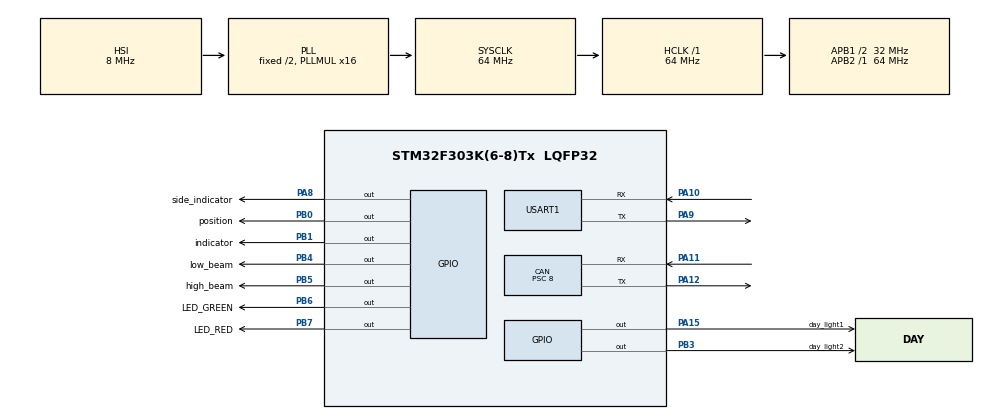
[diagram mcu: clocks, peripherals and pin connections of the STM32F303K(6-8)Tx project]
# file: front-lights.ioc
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CAN.BS1=CAN_BS1_6TQ
CAN.CalculateBaudRate=500000
CAN.CalculateTimeBit=2000
CAN.CalculateTimeQuantum=250.0
CAN.Prescaler=8
CAN.SJW=CAN_SJW_1TQ
Mcu.Family=STM32F3
Mcu.Name=STM32F303K(6-8)Tx
Mcu.Package=LQFP32
NVIC.CAN_RX0_IRQn=true\:0\:0\:false\:false\:true\:true\:true\:true
NVIC.CAN_RX1_IRQn=true\:0\:0\:false\:false\:true\:true\:true\:true
NVIC.PriorityGroup=NVIC_PRIORITYGROUP_4
PA10.Mode=Asynchronous
PA10.Signal=USART1_RX
PA11.Mode=CAN_Activate
PA11.Signal=CAN_RX
PA12.Mode=CAN_Activate
PA12.Signal=CAN_TX
PA13.Mode=Serial_Wire
PA13.Signal=SYS_JTMS-SWDIO
PA14.Mode=Serial_Wire
PA14.Signal=SYS_JTCK-SWCLK
PA15.GPIO_Label=day_light1
PA15.GPIO_PuPd=GPIO_PULLDOWN
PA15.Signal=GPIO_Output
PA8.GPIO_Label=side_indicator
PA8.GPIO_PuPd=GPIO_PULLDOWN
PA8.Signal=GPIO_Output
PA9.Mode=Asynchronous
PA9.Signal=USART1_TX
PB0.GPIO_Label=position
PB0.GPIO_PuPd=GPIO_PULLDOWN
PB0.Signal=GPIO_Output
PB1.GPIO_Label=indicator
PB1.GPIO_PuPd=GPIO_PULLDOWN
PB1.Signal=GPIO_Output
PB3.GPIO_Label=day_light2
PB3.GPIO_PuPd=GPIO_PULLDOWN
PB3.Signal=GPIO_Output
PB4.GPIO_Label=low_beam
PB4.GPIO_PuPd=GPIO_PULLDOWN
PB4.Signal=GPIO_Output
PB5.GPIO_Label=high_beam
PB5.GPIO_PuPd=GPIO_PULLDOWN
PB5.Signal=GPIO_Output
PB6.GPIO_Label=LED_GREEN
PB6.Signal=GPIO_Output
PB7.GPIO_Label=LED_RED
PB7.Signal=GPIO_Output
ProjectManager.HeapSize=0x200
ProjectManager.StackSize=0x400
ProjectManager.TargetToolchain=STM32CubeIDE
RCC.AHBFreq_Value=64000000
RCC.APB1CLKDivider=RCC_HCLK_DIV2
RCC.APB1Freq_Value=32000000
RCC.APB1TimFreq_Value=64000000
RCC.APB2Freq_Value=64000000
RCC.APB2TimFreq_Value=64000000
RCC.CortexFreq_Value=64000000
RCC.HCLKFreq_Value=64000000
RCC.HSE_VALUE=16000000
RCC.HSI_VALUE=8000000
RCC.PLLMUL=RCC_PLL_MUL16
RCC.RCC_PLLsource_Clock_Source_FROM_HSE=RCC_HSE_PREDIV_DIV2
RCC.SYSCLKFreq_VALUE=64000000
RCC.SYSCLKSourceVirtual=RCC_SYSCLKSOURCE_PLLCLK
USART1.VirtualMode-Asynchronous=VM_ASYNC
VP_TIM1_VS_ClockSourceINT.Mode=Internal
board=custom

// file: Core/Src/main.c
/* USER CODE BEGIN Header */
/**
  ******************************************************************************
  * @file           : main.c
  * @brief          : Main program body
  ******************************************************************************
  * @attention
  *
  * Copyright (c) 2026 STMicroelectronics.
  * All rights reserved.
  *
  * This software is licensed under terms that can be found in the LICENSE file
  * in the root directory of this software component.
  * If no LICENSE file comes with this software, it is provided AS-IS.
  *
  ******************************************************************************
  */
/* USER CODE END Header */
#include "main.h"
#include "can.h"
#include "tim.h"
#include "usart.h"
#include "gpio.h"

/* USER CODE BEGIN Includes */
#include "can_app.h"
#include "front_service.h"
/* USER CODE END Includes */

void SystemClock_Config(void);

int main(void)
{

  /* MCU Configuration--------------------------------------------------------*/

  /* Reset of all peripherals, Initializes the Flash interface and the Systick. */
  HAL_Init();

  /* Configure the system clock */
  SystemClock_Config();

  /* Initialize all configured peripherals */
  MX_GPIO_Init();
  MX_CAN_Init();
  MX_USART1_UART_Init();
  MX_TIM1_Init();
  /* USER CODE BEGIN 2 */
  FrontService();
  /* USER CODE END 2 */

  /* Infinite loop */
  while (1)
  {

  }
}

void SystemClock_Config(void)
{
  RCC_OscInitTypeDef RCC_OscInitStruct = {0};
  RCC_ClkInitTypeDef RCC_ClkInitStruct = {0};
  RCC_PeriphCLKInitTypeDef PeriphClkInit = {0};

  /** Initializes the RCC Oscillators according to the specified parameters
  * in the RCC_OscInitTypeDef structure.
  */
  RCC_OscInitStruct.OscillatorType = RCC_OSCILLATORTYPE_HSI;
  RCC_OscInitStruct.HSIState = RCC_HSI_ON;
  RCC_OscInitStruct.HSICalibrationValue = RCC_HSICALIBRATION_DEFAULT;
  RCC_OscInitStruct.PLL.PLLState = RCC_PLL_ON;
  RCC_OscInitStruct.PLL.PLLSource = RCC_PLLSOURCE_HSI;
  RCC_OscInitStruct.PLL.PLLMUL = RCC_PLL_MUL16;
  if (HAL_RCC_OscConfig(&RCC_OscInitStruct) != HAL_OK)
  {
    Error_Handler();
  }

  /** Initializes the CPU, AHB and APB buses clocks
  */
  RCC_ClkInitStruct.ClockType = RCC_CLOCKTYPE_HCLK|RCC_CLOCKTYPE_SYSCLK
                              |RCC_CLOCKTYPE_PCLK1|RCC_CLOCKTYPE_PCLK2;
  RCC_ClkInitStruct.SYSCLKSource = RCC_SYSCLKSOURCE_PLLCLK;
  RCC_ClkInitStruct.AHBCLKDivider = RCC_SYSCLK_DIV1;
  RCC_ClkInitStruct.APB1CLKDivider = RCC_HCLK_DIV2;
  RCC_ClkInitStruct.APB2CLKDivider = RCC_HCLK_DIV1;

  if (HAL_RCC_ClockConfig(&RCC_ClkInitStruct, FLASH_LATENCY_2) != HAL_OK)
  {
    Error_Handler();
  }
  PeriphClkInit.PeriphClockSelection = RCC_PERIPHCLK_USART1|RCC_PERIPHCLK_TIM1;
  PeriphClkInit.Usart1ClockSelection = RCC_USART1CLKSOURCE_PCLK1;
  PeriphClkInit.Tim1ClockSelection = RCC_TIM1CLK_HCLK;
  if (HAL_RCCEx_PeriphCLKConfig(&PeriphClkInit) != HAL_OK)
  {
    Error_Handler();
  }
}

void Error_Handler(void)
{
  __disable_irq();
  while (1)
  {
  }
}
